# KM1M7CF15 register map
Vendor: Nuvoton Technology Corporation Japan; Series: KM1M7CF; File version: 1.0.3
CPU: CM7 r1p2, little endian, MPU, FPU, double-precision FPU, I-cache, D-cache, ITCM, DTCM, 4 interrupt priority bits
Registers are 32-bit, read-write, no defined reset value unless marked. A register's access mark holds for its fields unless they carry their own. Offsets are from the block's base; [hi:lo] are bit positions; 'fields as' and 'values as' point back to an identical list.

## DAC — D/A Converter
Base 0x40027000
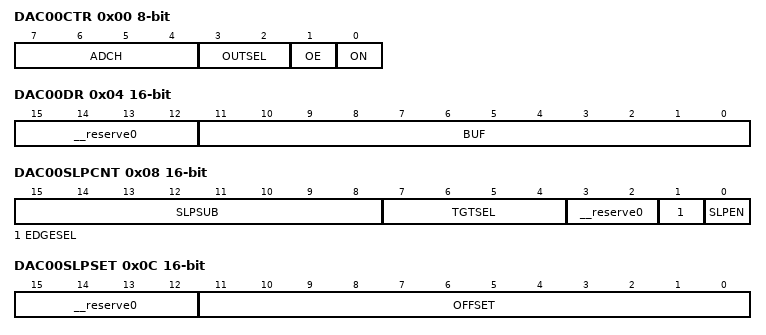
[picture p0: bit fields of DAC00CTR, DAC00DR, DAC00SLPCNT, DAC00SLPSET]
0x00 DAC00CTR 8-bit — DAC00 Control Register
  [7:4] ADCH — ADC conversion data buffer selection for DAC output
  [3:2] OUTSEL — DAOUT pin output data
  [1] OE — DAOUT pin output enable
  [0] ON — Operation control of D/A converter
0x04 DAC00DR 16-bit access per field — DAC00 Input Data Register
  [15:12] __reserve0 ro — "0" is always read out.
  [11:0] BUF rw — Set the input data that performs D/A conversion by DACn.
0x08 DAC00SLPCNT 16-bit access per field — DAC00 Slope Compensation Control Register
  [15:8] SLPSUB rw — Set slope compensation subtraction value.
  [7:4] TGTSEL rw — Slope compensation pin selection
  [3:2] __reserve0 ro — "0" is always read out.
  [1] EDGESEL rw — Slope compensation pin edge selection
  [0] SLPEN rw — D/An slope compensation enable
0x0C DAC00SLPSET 16-bit access per field — DAC00 Slope Compensation Setting Register
  [15:12] __reserve0 ro — "0" is always read out.
  [11:0] OFFSET rw — Set slope compensation subtraction start offset value.
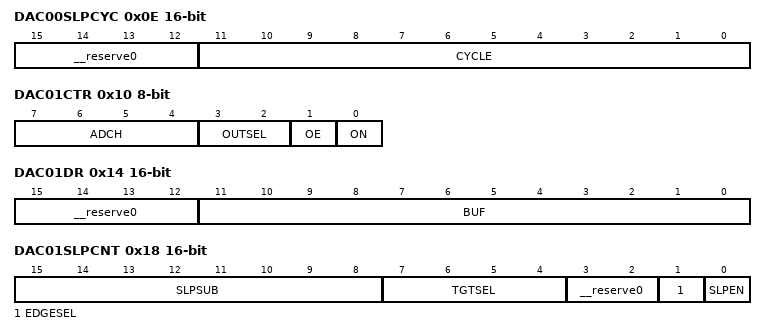
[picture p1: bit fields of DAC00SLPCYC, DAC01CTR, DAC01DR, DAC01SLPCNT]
0x0E DAC00SLPCYC 16-bit access per field — DAC00 Slope Compensation Cycle Register
  [15:12] __reserve0 ro — "0" is always read out.
  [11:0] CYCLE rw — Set slope compensation subtraction cycle.
0x10 DAC01CTR 8-bit — DAC01 Control Register
  fields as DAC00CTR
0x14 DAC01DR 16-bit access per field — DAC01 Input Data Register
  fields as DAC00DR
0x18 DAC01SLPCNT 16-bit access per field — DAC01 Slope Compensation Control Register
  fields as DAC00SLPCNT
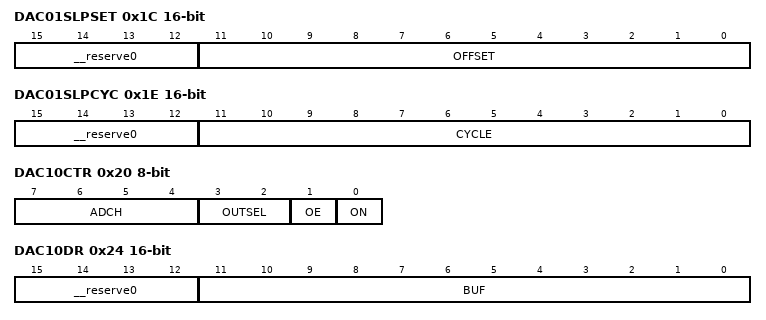
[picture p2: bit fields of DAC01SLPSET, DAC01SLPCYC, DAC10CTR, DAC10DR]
0x1C DAC01SLPSET 16-bit access per field — DAC01 Slope Compensation Setting Register
  fields as DAC00SLPSET
0x1E DAC01SLPCYC 16-bit access per field — DAC01 Slope Compensation Cycle Register
  fields as DAC00SLPCYC
0x20 DAC10CTR 8-bit — DAC10 Control Register
  fields as DAC00CTR
0x24 DAC10DR 16-bit access per field — DAC10 Input Data Register
  fields as DAC00DR
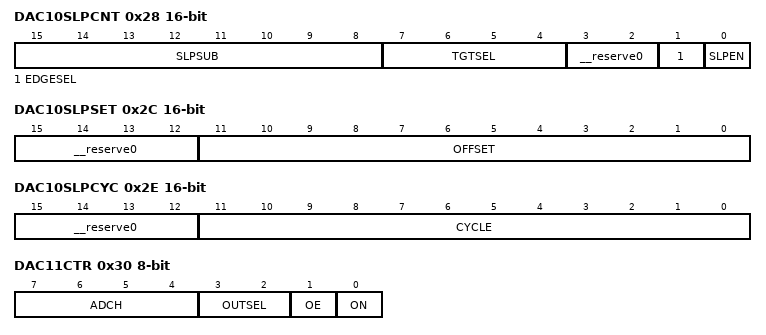
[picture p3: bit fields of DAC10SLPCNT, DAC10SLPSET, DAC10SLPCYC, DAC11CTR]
0x28 DAC10SLPCNT 16-bit access per field — DAC10 Slope Compensation Control Register
  fields as DAC00SLPCNT
0x2C DAC10SLPSET 16-bit access per field — DAC10 Slope Compensation Setting Register
  fields as DAC00SLPSET
0x2E DAC10SLPCYC 16-bit access per field — DAC10 Slope Compensation Cycle Register
  fields as DAC00SLPCYC
0x30 DAC11CTR 8-bit — DAC11 Control Register
  fields as DAC00CTR
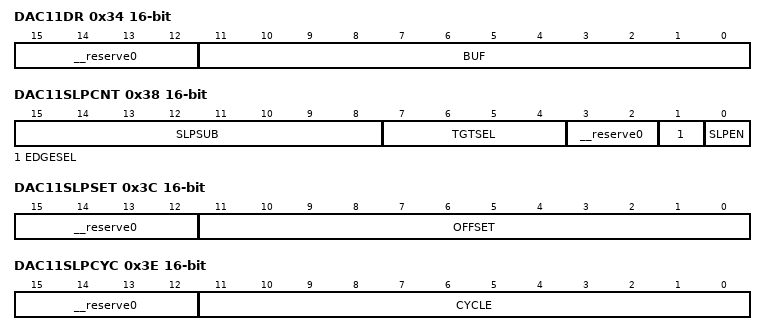
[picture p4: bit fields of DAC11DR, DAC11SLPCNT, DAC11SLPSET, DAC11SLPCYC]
0x34 DAC11DR 16-bit access per field — DAC11 Input Data Register
  fields as DAC00DR
0x38 DAC11SLPCNT 16-bit access per field — DAC11 Slope Compensation Control Register
  fields as DAC00SLPCNT
0x3C DAC11SLPSET 16-bit access per field — DAC11 Slope Compensation Setting Register
  fields as DAC00SLPSET
0x3E DAC11SLPCYC 16-bit access per field — DAC11 Slope Compensation Cycle Register
  fields as DAC00SLPCYC
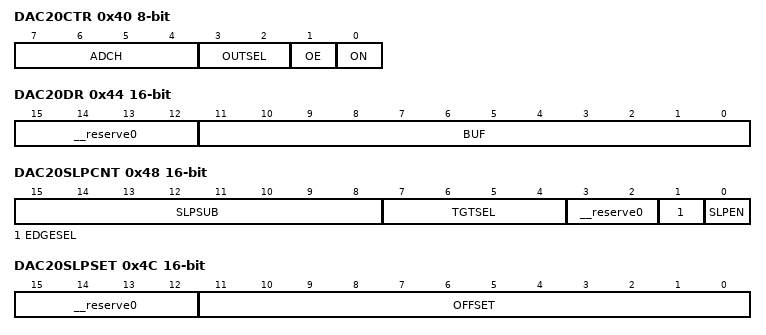
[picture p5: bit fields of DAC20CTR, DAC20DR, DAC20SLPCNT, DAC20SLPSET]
0x40 DAC20CTR 8-bit — DAC20 Control Register
  fields as DAC00CTR
0x44 DAC20DR 16-bit access per field — DAC20 Input Data Register
  fields as DAC00DR
0x48 DAC20SLPCNT 16-bit access per field — DAC20 Slope Compensation Control Register
  fields as DAC00SLPCNT
0x4C DAC20SLPSET 16-bit access per field — DAC20 Slope Compensation Setting Register
  fields as DAC00SLPSET
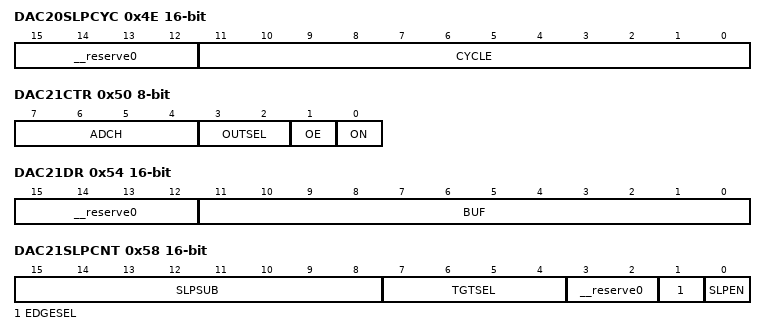
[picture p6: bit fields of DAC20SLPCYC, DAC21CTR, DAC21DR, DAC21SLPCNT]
0x4E DAC20SLPCYC 16-bit access per field — DAC20 Slope Compensation Cycle Register
  fields as DAC00SLPCYC
0x50 DAC21CTR 8-bit — DAC21 Control Register
  fields as DAC00CTR
0x54 DAC21DR 16-bit access per field — DAC21 Input Data Register
  fields as DAC00DR
0x58 DAC21SLPCNT 16-bit access per field — DAC21 Slope Compensation Control Register
  fields as DAC00SLPCNT
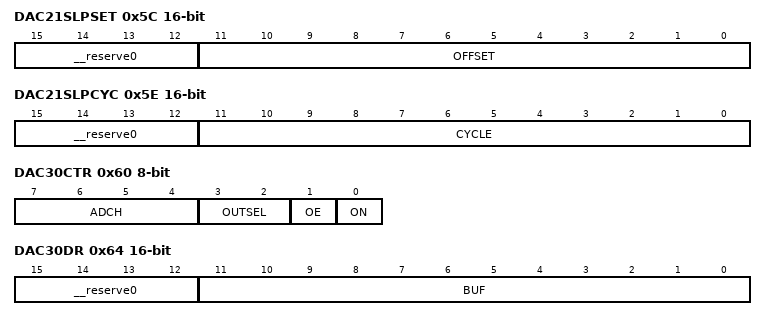
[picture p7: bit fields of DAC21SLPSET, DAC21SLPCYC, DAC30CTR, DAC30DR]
0x5C DAC21SLPSET 16-bit access per field — DAC21 Slope Compensation Setting Register
  fields as DAC00SLPSET
0x5E DAC21SLPCYC 16-bit access per field — DAC21 Slope Compensation Cycle Register
  fields as DAC00SLPCYC
0x60 DAC30CTR 8-bit — DAC30 Control Register
  fields as DAC00CTR
0x64 DAC30DR 16-bit access per field — DAC30 Input Data Register
  fields as DAC00DR
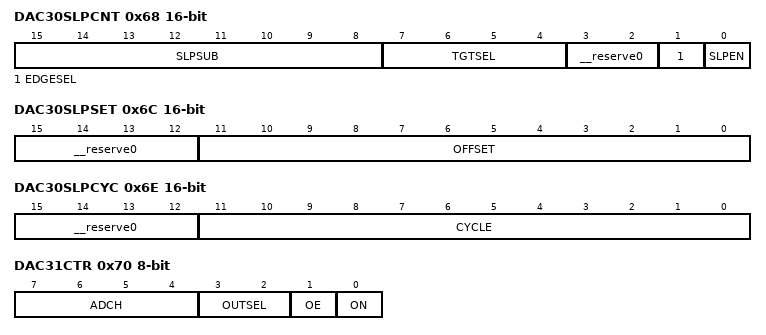
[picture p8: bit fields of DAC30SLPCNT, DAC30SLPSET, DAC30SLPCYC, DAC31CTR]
0x68 DAC30SLPCNT 16-bit access per field — DAC30 Slope Compensation Control Register
  fields as DAC00SLPCNT
0x6C DAC30SLPSET 16-bit access per field — DAC30 Slope Compensation Setting Register
  fields as DAC00SLPSET
0x6E DAC30SLPCYC 16-bit access per field — DAC30 Slope Compensation Cycle Register
  fields as DAC00SLPCYC
0x70 DAC31CTR 8-bit — DAC31 Control Register
  fields as DAC00CTR
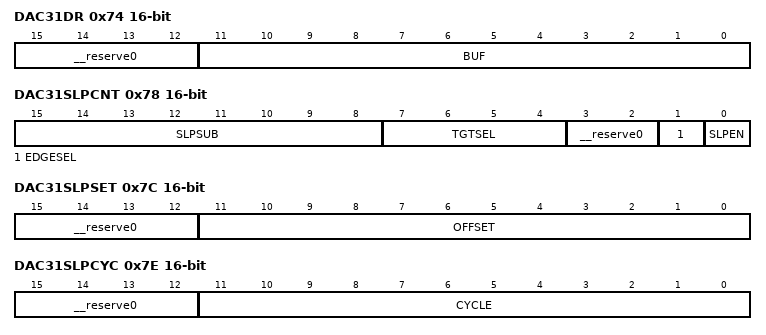
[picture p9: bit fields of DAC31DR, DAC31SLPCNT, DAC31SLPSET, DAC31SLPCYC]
0x74 DAC31DR 16-bit access per field — DAC31 Input Data Register
  fields as DAC00DR
0x78 DAC31SLPCNT 16-bit access per field — DAC31 Slope Compensation Control Register
  fields as DAC00SLPCNT
0x7C DAC31SLPSET 16-bit access per field — DAC31 Slope Compensation Setting Register
  fields as DAC00SLPSET
0x7E DAC31SLPCYC 16-bit access per field — DAC31 Slope Compensation Cycle Register
  fields as DAC00SLPCYC
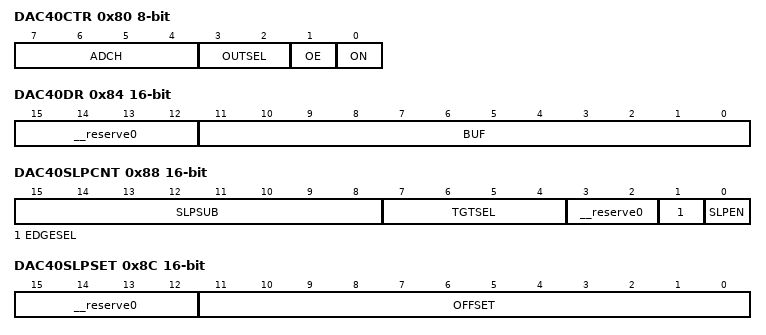
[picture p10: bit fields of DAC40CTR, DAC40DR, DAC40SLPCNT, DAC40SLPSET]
0x80 DAC40CTR 8-bit — DAC40 Control Register
  fields as DAC00CTR
0x84 DAC40DR 16-bit access per field — DAC40 Input Data Register
  fields as DAC00DR
0x88 DAC40SLPCNT 16-bit access per field — DAC40 Slope Compensation Control Register
  fields as DAC00SLPCNT
0x8C DAC40SLPSET 16-bit access per field — DAC40 Slope Compensation Setting Register
  fields as DAC00SLPSET
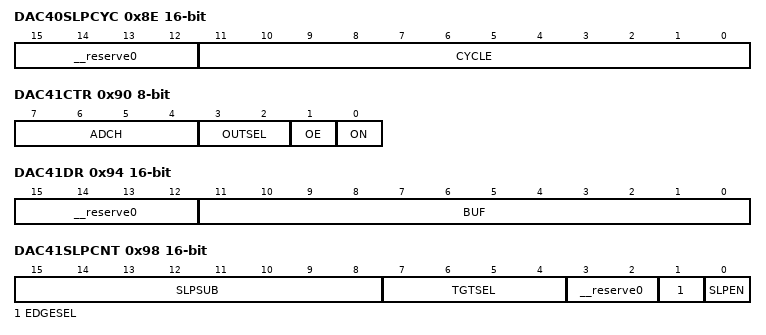
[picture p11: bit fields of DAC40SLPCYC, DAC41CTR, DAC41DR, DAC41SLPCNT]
0x8E DAC40SLPCYC 16-bit access per field — DAC40 Slope Compensation Cycle Register
  fields as DAC00SLPCYC
0x90 DAC41CTR 8-bit — DAC41 Control Register
  fields as DAC00CTR
0x94 DAC41DR 16-bit access per field — DAC41 Input Data Register
  fields as DAC00DR
0x98 DAC41SLPCNT 16-bit access per field — DAC41 Slope Compensation Control Register
  fields as DAC00SLPCNT
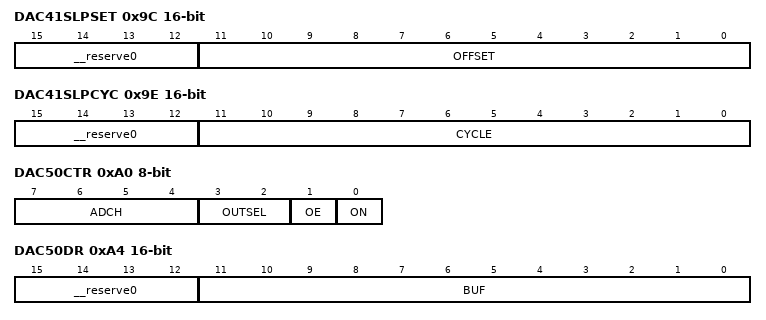
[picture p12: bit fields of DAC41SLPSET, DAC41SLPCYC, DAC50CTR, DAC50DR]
0x9C DAC41SLPSET 16-bit access per field — DAC41 Slope Compensation Setting Register
  fields as DAC00SLPSET
0x9E DAC41SLPCYC 16-bit access per field — DAC41 Slope Compensation Cycle Register
  fields as DAC00SLPCYC
0xA0 DAC50CTR 8-bit — DAC50 Control Register
  fields as DAC00CTR
0xA4 DAC50DR 16-bit access per field — DAC50 Input Data Register
  fields as DAC00DR
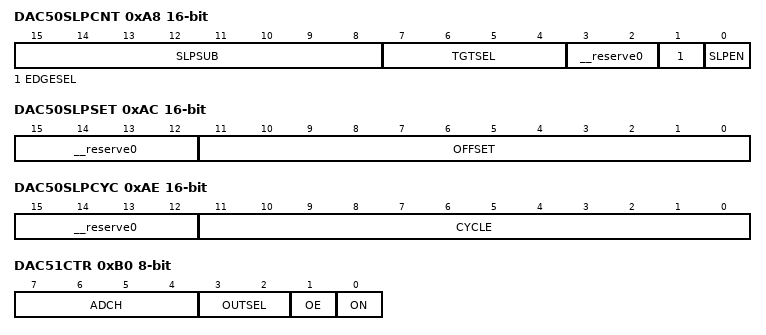
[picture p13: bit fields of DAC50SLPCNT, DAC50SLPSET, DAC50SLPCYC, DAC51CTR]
0xA8 DAC50SLPCNT 16-bit access per field — DAC50 Slope Compensation Control Register
  fields as DAC00SLPCNT
0xAC DAC50SLPSET 16-bit access per field — DAC50 Slope Compensation Setting Register
  fields as DAC00SLPSET
0xAE DAC50SLPCYC 16-bit access per field — DAC50 Slope Compensation Cycle Register
  fields as DAC00SLPCYC
0xB0 DAC51CTR 8-bit — DAC51 Control Register
  fields as DAC00CTR
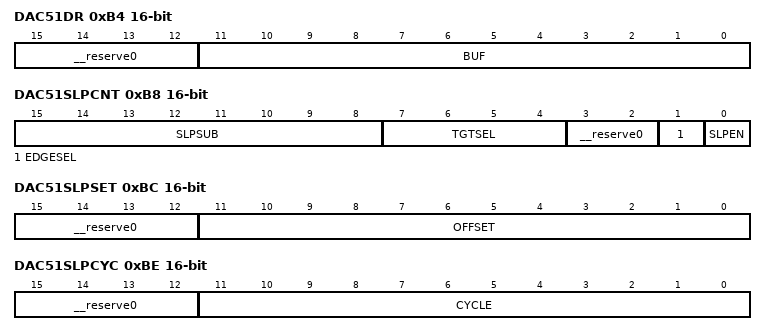
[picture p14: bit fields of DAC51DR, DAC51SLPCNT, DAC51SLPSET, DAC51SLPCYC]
0xB4 DAC51DR 16-bit access per field — DAC51 Input Data Register
  fields as DAC00DR
0xB8 DAC51SLPCNT 16-bit access per field — DAC51 Slope Compensation Control Register
  fields as DAC00SLPCNT
0xBC DAC51SLPSET 16-bit access per field — DAC51 Slope Compensation Setting Register
  fields as DAC00SLPSET
0xBE DAC51SLPCYC 16-bit access per field — DAC51 Slope Compensation Cycle Register
  fields as DAC00SLPCYC
